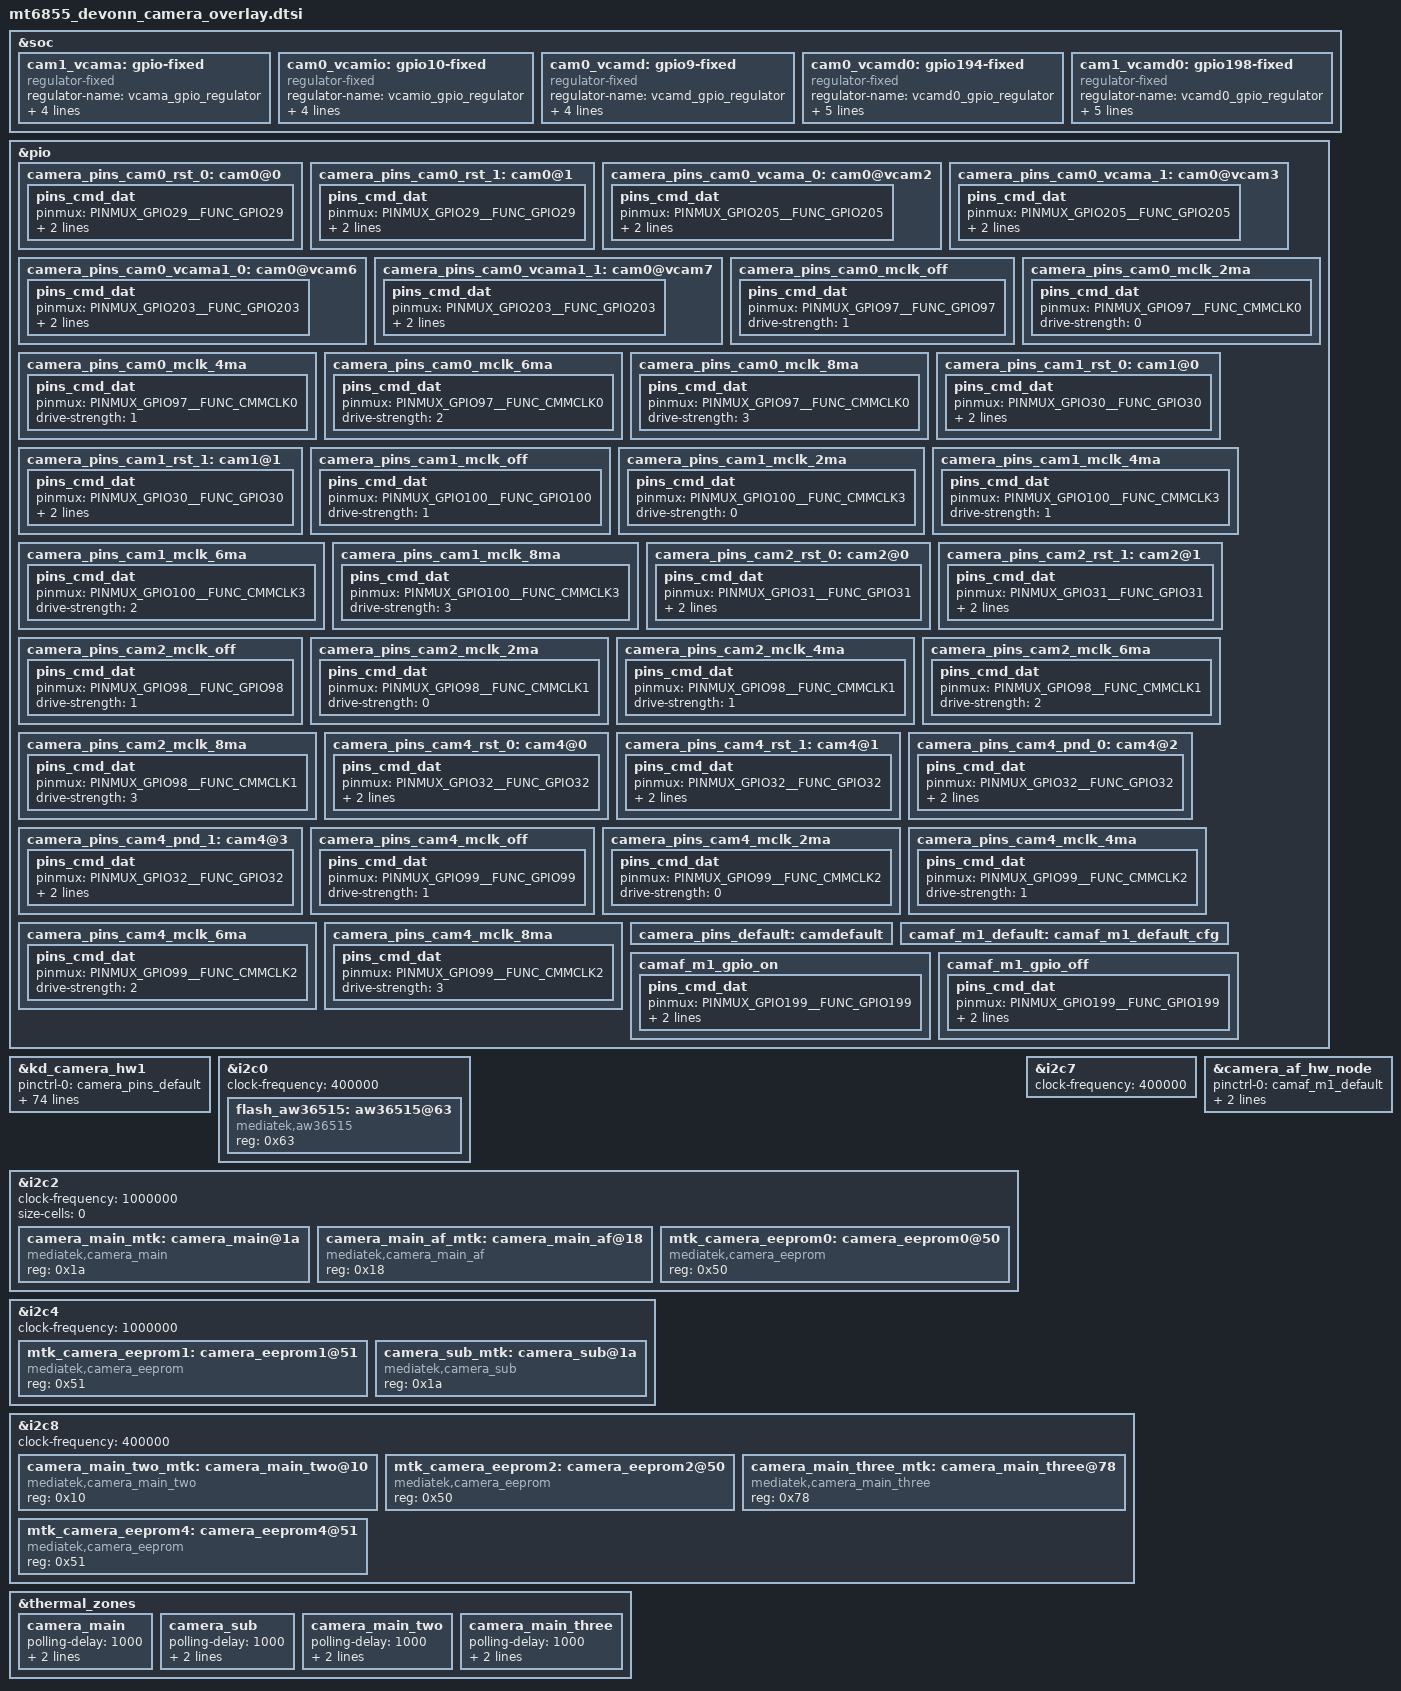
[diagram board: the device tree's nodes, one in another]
// SPDX-License-Identifier: GPL-2.0
/* Copyright (c) 2020 MediaTek Inc. */
/* CAMERA GPIO standardization */
&soc {
		cam1_vcama:gpio-fixed {
			compatible = "regulator-fixed";
			regulator-name = "vcama_gpio_regulator";
			regulator-min-microvolt = <2800000>;
			regulator-max-microvolt = <2800000>;
			gpio = <&pio 195 0x0>;
			enable-active-high;
			status = "okay";
		};

		cam0_vcamio:gpio10-fixed {
			compatible = "regulator-fixed";
			regulator-name = "vcamio_gpio_regulator";
			regulator-min-microvolt = <1800000>;
			regulator-max-microvolt = <1800000>;
			gpio = <&pio 10 0x0>;
			enable-active-high;
			status = "okay";
		};

		cam0_vcamd:gpio9-fixed {
			compatible = "regulator-fixed";
			regulator-name = "vcamd_gpio_regulator";
			regulator-min-microvolt = <1100000>;
			regulator-max-microvolt = <1100000>;
			gpio = <&pio 9 0x0>;
			enable-active-high;
			status = "okay";
		};

		cam0_vcamd0:gpio194-fixed {
			compatible = "regulator-fixed";
			regulator-name = "vcamd0_gpio_regulator";
			vin-supply = <&cam0_vcamd>;
			regulator-min-microvolt = <1100000>;
			regulator-max-microvolt = <1100000>;
			gpio = <&pio 194 0x0>;
			enable-active-high;
			status = "okay";
		};

		cam1_vcamd0:gpio198-fixed {
			compatible = "regulator-fixed";
			regulator-name = "vcamd0_gpio_regulator";
			vin-supply = <&cam0_vcamd>;
			regulator-min-microvolt = <1100000>;
			regulator-max-microvolt = <1100000>;
			gpio = <&pio 198 0x0>;
			enable-active-high;
			status = "okay";
		};
};

&pio {
	camera_pins_cam0_rst_0: cam0@0 {
		pins_cmd_dat {
			pinmux = <PINMUX_GPIO29__FUNC_GPIO29>;
			slew-rate = <1>;
			output-low;
		};
	};
	camera_pins_cam0_rst_1: cam0@1 {
		pins_cmd_dat {
			pinmux = <PINMUX_GPIO29__FUNC_GPIO29>;
			slew-rate = <1>;
			output-high;
		};
	};

	camera_pins_cam0_vcama_0: cam0@vcam2 {
		pins_cmd_dat {
			pinmux = <PINMUX_GPIO205__FUNC_GPIO205>;
			slew-rate = <1>;
			output-low;
		};
	};
	camera_pins_cam0_vcama_1: cam0@vcam3 {
		pins_cmd_dat {
			pinmux = <PINMUX_GPIO205__FUNC_GPIO205>;
			slew-rate = <1>;
			output-high;
		};
	};

	camera_pins_cam0_vcama1_0: cam0@vcam6 {
		pins_cmd_dat {
			pinmux = <PINMUX_GPIO203__FUNC_GPIO203>;/*1v1 enable*/
			slew-rate = <1>;
			output-low;
		};
	};
	camera_pins_cam0_vcama1_1: cam0@vcam7 {
		pins_cmd_dat {
			pinmux = <PINMUX_GPIO203__FUNC_GPIO203>;
			slew-rate = <1>;
			output-high;
		};
	};

	camera_pins_cam0_mclk_off: camera_pins_cam0_mclk_off {
		pins_cmd_dat {
			pinmux = <PINMUX_GPIO97__FUNC_GPIO97>;
			drive-strength = <1>;
		};
	};
	camera_pins_cam0_mclk_2ma: camera_pins_cam0_mclk_2ma {
		pins_cmd_dat {
			pinmux = <PINMUX_GPIO97__FUNC_CMMCLK0>;
			drive-strength = <0>;
		};
	};
	camera_pins_cam0_mclk_4ma: camera_pins_cam0_mclk_4ma {
		pins_cmd_dat {
			pinmux = <PINMUX_GPIO97__FUNC_CMMCLK0>;
			drive-strength = <1>;
		};
	};
	camera_pins_cam0_mclk_6ma: camera_pins_cam0_mclk_6ma {
		pins_cmd_dat {
			pinmux = <PINMUX_GPIO97__FUNC_CMMCLK0>;
			drive-strength = <2>;
		};
	};
	camera_pins_cam0_mclk_8ma: camera_pins_cam0_mclk_8ma {
		pins_cmd_dat {
			pinmux = <PINMUX_GPIO97__FUNC_CMMCLK0>;
			drive-strength = <3>;
		};
	};


	camera_pins_cam1_rst_0: cam1@0 {
		pins_cmd_dat {
			pinmux = <PINMUX_GPIO30__FUNC_GPIO30>;
			slew-rate = <1>;
			output-low;
		};
	};
	camera_pins_cam1_rst_1: cam1@1 {
			pins_cmd_dat {
					pinmux = <PINMUX_GPIO30__FUNC_GPIO30>;
					slew-rate = <1>;
					output-high;
			};
	};

       camera_pins_cam1_mclk_off: camera_pins_cam1_mclk_off {
			pins_cmd_dat {
					pinmux = <PINMUX_GPIO100__FUNC_GPIO100>;
					drive-strength = <1>;
			};
	};
	camera_pins_cam1_mclk_2ma: camera_pins_cam1_mclk_2ma {
			pins_cmd_dat {
					pinmux = <PINMUX_GPIO100__FUNC_CMMCLK3>;
					drive-strength = <0>;
			};
	};
	camera_pins_cam1_mclk_4ma: camera_pins_cam1_mclk_4ma {
			pins_cmd_dat {
					pinmux = <PINMUX_GPIO100__FUNC_CMMCLK3>;
					drive-strength = <1>;
			};
	};
	camera_pins_cam1_mclk_6ma: camera_pins_cam1_mclk_6ma {
			pins_cmd_dat {
					pinmux = <PINMUX_GPIO100__FUNC_CMMCLK3>;
					drive-strength = <2>;
			};
	};
	camera_pins_cam1_mclk_8ma: camera_pins_cam1_mclk_8ma {
			pins_cmd_dat {
					pinmux = <PINMUX_GPIO100__FUNC_CMMCLK3>;
					drive-strength = <3>;
			};
	};

	camera_pins_cam2_rst_0: cam2@0 {
			pins_cmd_dat {
					pinmux = <PINMUX_GPIO31__FUNC_GPIO31>;
					slew-rate = <1>;
					output-low;
			};
	};
	camera_pins_cam2_rst_1: cam2@1 {
			pins_cmd_dat {
					pinmux = <PINMUX_GPIO31__FUNC_GPIO31>;
					slew-rate = <1>;
					output-high;
			};
	};

	camera_pins_cam2_mclk_off: camera_pins_cam2_mclk_off {
			pins_cmd_dat {
					pinmux = <PINMUX_GPIO98__FUNC_GPIO98>;
					drive-strength = <1>;
			};
	};
	camera_pins_cam2_mclk_2ma: camera_pins_cam2_mclk_2ma {
			pins_cmd_dat {
					pinmux = <PINMUX_GPIO98__FUNC_CMMCLK1>;
					drive-strength = <0>;
			};
	};
	camera_pins_cam2_mclk_4ma: camera_pins_cam2_mclk_4ma {
			pins_cmd_dat {
					pinmux = <PINMUX_GPIO98__FUNC_CMMCLK1>;
					drive-strength = <1>;
			};
	};
	camera_pins_cam2_mclk_6ma: camera_pins_cam2_mclk_6ma {
			pins_cmd_dat {
					pinmux = <PINMUX_GPIO98__FUNC_CMMCLK1>;
					drive-strength = <2>;
			};
	};
	camera_pins_cam2_mclk_8ma: camera_pins_cam2_mclk_8ma {
			pins_cmd_dat {
					pinmux = <PINMUX_GPIO98__FUNC_CMMCLK1>;
					drive-strength = <3>;
			};
	};
	camera_pins_cam4_rst_0: cam4@0 {
		pins_cmd_dat {
			pinmux = <PINMUX_GPIO32__FUNC_GPIO32>;
			slew-rate = <1>;
			output-low;
		};
	};
	camera_pins_cam4_rst_1: cam4@1 {
		pins_cmd_dat {
			pinmux = <PINMUX_GPIO32__FUNC_GPIO32>;
			slew-rate = <1>;
			output-high;
		};
	};
	camera_pins_cam4_pnd_0: cam4@2 {
		pins_cmd_dat {
			pinmux = <PINMUX_GPIO32__FUNC_GPIO32>;
			slew-rate = <1>;
			output-low;
		};
	};
	camera_pins_cam4_pnd_1: cam4@3 {
		pins_cmd_dat {
			pinmux = <PINMUX_GPIO32__FUNC_GPIO32>;
			slew-rate = <1>;
			output-high;
		};
	};
	camera_pins_cam4_mclk_off: camera_pins_cam4_mclk_off {
		pins_cmd_dat {
			pinmux = <PINMUX_GPIO99__FUNC_GPIO99>;
			drive-strength = <1>;
		};
	};
	camera_pins_cam4_mclk_2ma: camera_pins_cam4_mclk_2ma {
		pins_cmd_dat {
			pinmux = <PINMUX_GPIO99__FUNC_CMMCLK2>;
			drive-strength = <0>;
		};
	};
	camera_pins_cam4_mclk_4ma: camera_pins_cam4_mclk_4ma {
		pins_cmd_dat {
			pinmux = <PINMUX_GPIO99__FUNC_CMMCLK2>;
			drive-strength = <1>;
		};
	};
	camera_pins_cam4_mclk_6ma: camera_pins_cam4_mclk_6ma {
		pins_cmd_dat {
			pinmux = <PINMUX_GPIO99__FUNC_CMMCLK2>;
			drive-strength = <2>;
		};
	};
	camera_pins_cam4_mclk_8ma: camera_pins_cam4_mclk_8ma {
		pins_cmd_dat {
			pinmux = <PINMUX_GPIO99__FUNC_CMMCLK2>;
			drive-strength = <3>;
		};
	};

	camera_pins_default: camdefault {
	};

	camaf_m1_default: camaf_m1_default_cfg{

	};
	camaf_m1_gpio_on: camaf_m1_gpio_on {
		pins_cmd_dat {
			pinmux = <PINMUX_GPIO199__FUNC_GPIO199>;
			slew-rate = <1>;
			output-high;
		};
	};
	camaf_m1_gpio_off: camaf_m1_gpio_off {
		pins_cmd_dat {
			pinmux = <PINMUX_GPIO199__FUNC_GPIO199>;
			slew-rate = <1>;
			output-low;
		};
	};

};
&kd_camera_hw1 {
	pinctrl-names = "default",
			"cam0_rst0", "cam0_rst1",
			"cam1_rst0", "cam1_rst1",
			"cam2_rst0", "cam2_rst1",
			"cam4_rst0", "cam4_rst1",
			"cam0_ldo_vcama_0", "cam0_ldo_vcama_1",
			"cam0_ldo_vcama1_0", "cam0_ldo_vcama1_1",
			"cam1_ldo_vcamd_0", "cam1_ldo_vcamd_1",
			"cam0_mclk_off",
			"cam0_mclk_2mA", "cam0_mclk_4mA",
			"cam0_mclk_6mA", "cam0_mclk_8mA",
			"cam1_mclk_off",
			"cam1_mclk_2mA", "cam1_mclk_4mA",
			"cam1_mclk_6mA", "cam1_mclk_8mA",
			"cam2_mclk_off",
			"cam2_mclk_2mA", "cam2_mclk_4mA",
			"cam2_mclk_6mA", "cam2_mclk_8mA",
			"cam4_mclk_off",
			"cam4_mclk_2mA", "cam4_mclk_4mA",
			"cam4_mclk_6mA", "cam4_mclk_8mA";

	pinctrl-0 = <&camera_pins_default>;
	pinctrl-1 = <&camera_pins_cam0_rst_0>;
	pinctrl-2 = <&camera_pins_cam0_rst_1>;
	pinctrl-3 = <&camera_pins_cam1_rst_0>;
	pinctrl-4 = <&camera_pins_cam1_rst_1>;
	pinctrl-5 = <&camera_pins_cam2_rst_0>;
	pinctrl-6 = <&camera_pins_cam2_rst_1>;
	pinctrl-7 = <&camera_pins_cam4_rst_0>;
	pinctrl-8 = <&camera_pins_cam4_rst_1>;
	pinctrl-9 = <&camera_pins_cam0_vcama_0>;
	pinctrl-10 = <&camera_pins_cam0_vcama_1>;
	pinctrl-11 = <&camera_pins_cam0_vcama1_0>;
	pinctrl-12 = <&camera_pins_cam0_vcama1_1>;
	pinctrl-13 = <&camera_pins_cam0_mclk_off>;
	pinctrl-14 = <&camera_pins_cam0_mclk_2ma>;
	pinctrl-15 = <&camera_pins_cam0_mclk_4ma>;
	pinctrl-16 = <&camera_pins_cam0_mclk_6ma>;
	pinctrl-17 = <&camera_pins_cam0_mclk_8ma>;
	pinctrl-18 = <&camera_pins_cam1_mclk_off>;
	pinctrl-19 = <&camera_pins_cam1_mclk_2ma>;
	pinctrl-20 = <&camera_pins_cam1_mclk_4ma>;
	pinctrl-21 = <&camera_pins_cam1_mclk_6ma>;
	pinctrl-22 = <&camera_pins_cam1_mclk_8ma>;
	pinctrl-23 = <&camera_pins_cam2_mclk_off>;
	pinctrl-24 = <&camera_pins_cam2_mclk_2ma>;
	pinctrl-25 = <&camera_pins_cam2_mclk_4ma>;
	pinctrl-26 = <&camera_pins_cam2_mclk_6ma>;
	pinctrl-27 = <&camera_pins_cam2_mclk_8ma>;
	pinctrl-28 = <&camera_pins_cam4_mclk_off>;
	pinctrl-29 = <&camera_pins_cam4_mclk_2ma>;
	pinctrl-30 = <&camera_pins_cam4_mclk_4ma>;
	pinctrl-31 = <&camera_pins_cam4_mclk_6ma>;
	pinctrl-32 = <&camera_pins_cam4_mclk_8ma>;

	cam1_vcama-supply = <&cam1_vcama>;
	cam2_vcama-supply = <&cam1_vcama>;
	cam3_vcama-supply = <&cam1_vcama>;
	cam4_vcama-supply = <&cam1_vcama>;

	cam0_vcamio-supply = <&cam0_vcamio>;
	cam1_vcamio-supply = <&cam0_vcamio>;
	cam2_vcamio-supply = <&cam0_vcamio>;
	cam3_vcamio-supply = <&cam0_vcamio>;
	cam4_vcamio-supply = <&cam0_vcamio>;

	cam0_vcamd-supply = <&cam0_vcamd0>;
	cam1_vcamd-supply = <&cam1_vcamd0>;

	cam0_pin_mclk = "mclk";
	cam0_pin_rst = "gpio";
	cam0_pin_vcama = "gpio";
	cam0_pin_vcama1 = "gpio";
	cam0_pin_vcamd = "regulator";
	cam0_pin_vcamio = "regulator";
	cam1_pin_mclk = "mclk";
	cam1_pin_rst = "gpio";
	cam1_pin_vcama = "regulator";
	cam1_pin_vcamd = "regulator";
	cam1_pin_vcamio = "regulator";
	cam1_pin_mipi_switch_en = "gpio";
	cam1_pin_mipi_switch_sel = "gpio";
	cam2_pin_mclk = "mclk";
	cam2_pin_pdn = "gpio";
	cam2_pin_rst = "gpio";
	cam2_pin_vcama = "regulator";
	cam2_pin_vcamd = "gpio";
	cam2_pin_vcamio = "regulator";
#if 0
	cam3_pin_mclk = "mclk";
	cam3_pin_pdn = "gpio";
	cam3_pin_rst = "gpio";
	cam3_pin_vcama = "regulator";
	cam3_pin_vcamd = "gpio";
	cam3_pin_vcamio = "regulator";
#endif
	cam4_pin_mclk = "mclk";
	cam4_pin_pdn = "gpio";
	cam4_pin_rst = "gpio";
	cam4_pin_vcama = "regulator";
	cam4_pin_vcamd = "gpio";
	cam4_pin_vcamio = "regulator";

	cam0_enable_sensor = "mot_devonn_s5kjn1_mipi_raw";
	cam1_enable_sensor = "mot_devonn_hi1634q_mipi_raw";
	cam2_enable_sensor = "mot_devonn_gc02m1_mipi_raw";
	//cam3_enable_sensor = "null_mipi_raw";
	cam4_enable_sensor = "mot_devonn_ov02b10_mipi_raw";

	status = "okay";
};
/* CAMERA GPIO end */

&i2c0 {
        status = "okay";
        clock-frequency = <400000>;
        flash_aw36515:aw36515@63 {
        compatible = "mediatek,aw36515";
        reg = <0x63>;
        status = "okay";
        };
};

/* CAMERA EEPROM */
&i2c2 {
	status = "okay";
	clock-frequency = <1000000>;
	#address-cells = <1>;
	size-cells = <0>;

	camera_main_mtk:camera_main@1a {
		compatible = "mediatek,camera_main";
		#thermal-sensor-cells = <0>;
		reg = <0x1a>;
		status = "okay";
	};
	camera_main_af_mtk:camera_main_af@18 {
		compatible = "mediatek,camera_main_af";
		reg = <0x18>;
		status = "okay";
	};

	mtk_camera_eeprom0:camera_eeprom0@50 {
		compatible = "mediatek,camera_eeprom";
		reg = <0x50>;
		status = "okay";
	};
};
&i2c4 {
	status = "okay";
	clock-frequency = <1000000>;
	#address-cells = <1>;
	#size-cells = <0>;

	mtk_camera_eeprom1:camera_eeprom1@51 {
		compatible = "mediatek,camera_eeprom";
		reg = <0x51>;
		status = "okay";
	};

	camera_sub_mtk:camera_sub@1a {
		compatible = "mediatek,camera_sub";
		#thermal-sensor-cells = <0>;
		reg = <0x1a>;
		status = "okay";
	};
};
&i2c7 {
	status = "okay";
	clock-frequency = <400000>;
	#address-cells = <1>;
	#size-cells = <0>;

};
&i2c8 {
	status = "okay";
	clock-frequency = <400000>;
	#address-cells = <1>;
	#size-cells = <0>;

	camera_main_two_mtk:camera_main_two@10 {
		compatible = "mediatek,camera_main_two";
		#thermal-sensor-cells = <0>;
		reg = <0x10>;
		status = "okay";
	};

	mtk_camera_eeprom2:camera_eeprom2@50 {
		compatible = "mediatek,camera_eeprom";
		reg = <0x50>;
		status = "okay";
	};

	camera_main_three_mtk:camera_main_three@78 {
		compatible = "mediatek,camera_main_three";
		#thermal-sensor-cells = <0>;
		reg = <0x78>;
		status = "okay";
	};
	mtk_camera_eeprom4:camera_eeprom4@51 {
		compatible = "mediatek,camera_eeprom";
		reg = <0x51>;
		status = "okay";
	};
};
/* CAMERA EEPROM end */

/* CAMERA TZ config */
&thermal_zones {
	camera_main: camera_main {
		polling-delay = <1000>; /* milliseconds */
		polling-delay-passive = <0>; /* milliseconds */
		thermal-sensors = <&camera_main_mtk>;
	};
	camera_sub: camera_sub {
		polling-delay = <1000>; /* milliseconds */
		polling-delay-passive = <0>; /* milliseconds */
		thermal-sensors = <&camera_sub_mtk>;
	};
	camera_main_two: camera_main_two {
		polling-delay = <1000>; /* milliseconds */
		polling-delay-passive = <0>; /* milliseconds */
		thermal-sensors = <&camera_main_two_mtk>;
	};
	camera_main_three: camera_main_three {
		polling-delay = <1000>; /* milliseconds */
		polling-delay-passive = <0>; /* milliseconds */
		thermal-sensors = <&camera_main_three_mtk>;
	};
};

&camera_af_hw_node {
	pinctrl-names = "camaf_m1_default", "camaf_m1_gpio_on", "camaf_m1_gpio_off";
	pinctrl-0 = <&camaf_m1_default>;
	pinctrl-1 = <&camaf_m1_gpio_on>;
	pinctrl-2 = <&camaf_m1_gpio_off>;
	status = "okay";
};

